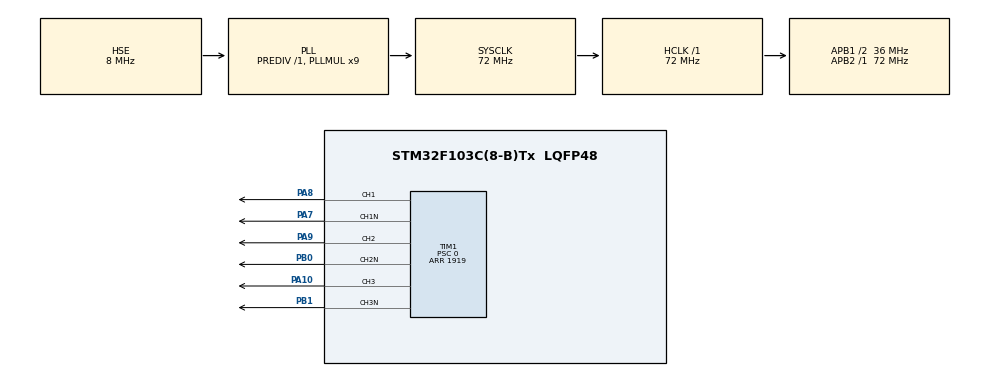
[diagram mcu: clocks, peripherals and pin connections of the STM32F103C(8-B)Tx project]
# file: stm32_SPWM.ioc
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Dma.Request0=TIM1_CH1
Dma.TIM1_CH1.0.Direction=DMA_MEMORY_TO_PERIPH
Dma.TIM1_CH1.0.Instance=DMA1_Channel2
Dma.TIM1_CH1.0.MemDataAlignment=DMA_MDATAALIGN_HALFWORD
Dma.TIM1_CH1.0.MemInc=DMA_MINC_ENABLE
Dma.TIM1_CH1.0.Mode=DMA_CIRCULAR
Dma.TIM1_CH1.0.PeriphDataAlignment=DMA_PDATAALIGN_HALFWORD
Dma.TIM1_CH1.0.PeriphInc=DMA_PINC_DISABLE
Dma.TIM1_CH1.0.Priority=DMA_PRIORITY_LOW
Mcu.Family=STM32F1
Mcu.Name=STM32F103C(8-B)Tx
Mcu.Package=LQFP48
NVIC.DMA1_Channel2_IRQn=true\:0\:0\:false\:false\:true\:false\:true\:true
NVIC.PriorityGroup=NVIC_PRIORITYGROUP_4
PA10.Signal=S_TIM1_CH3
PA7.Mode=PWM Generation1 CH1 CH1N
PA7.Signal=TIM1_CH1N
PA8.Signal=S_TIM1_CH1
PA9.Signal=S_TIM1_CH2
PB0.Mode=PWM Generation2 CH2 CH2N
PB0.Signal=TIM1_CH2N
PB1.Mode=PWM Generation3 CH3 CH3N
PB1.Signal=TIM1_CH3N
PD0-OSC_IN.Mode=HSE-External-Oscillator
PD0-OSC_IN.Signal=RCC_OSC_IN
PD1-OSC_OUT.Mode=HSE-External-Oscillator
PD1-OSC_OUT.Signal=RCC_OSC_OUT
ProjectManager.HeapSize=0x200
ProjectManager.StackSize=0x400
ProjectManager.TargetToolchain=STM32CubeIDE
RCC.AHBFreq_Value=72000000
RCC.APB1CLKDivider=RCC_HCLK_DIV2
RCC.APB1Freq_Value=36000000
RCC.APB1TimFreq_Value=72000000
RCC.APB2Freq_Value=72000000
RCC.APB2TimFreq_Value=72000000
RCC.HCLKFreq_Value=72000000
RCC.PLLMUL=RCC_PLL_MUL9
RCC.PLLSourceVirtual=RCC_PLLSOURCE_HSE
RCC.SYSCLKFreq_VALUE=72000000
RCC.SYSCLKSource=RCC_SYSCLKSOURCE_PLLCLK
RCC.USBFreq_Value=72000000
SH.S_TIM1_CH1.0=TIM1_CH1,PWM Generation1 CH1 CH1N
SH.S_TIM1_CH2.0=TIM1_CH2,PWM Generation2 CH2 CH2N
SH.S_TIM1_CH3.0=TIM1_CH3,PWM Generation3 CH3 CH3N
TIM1.AutoReloadPreload=TIM_AUTORELOAD_PRELOAD_ENABLE
TIM1.Channel-PWM\ Generation1\ CH1\ CH1N=TIM_CHANNEL_1
TIM1.Channel-PWM\ Generation2\ CH2\ CH2N=TIM_CHANNEL_2
TIM1.Channel-PWM\ Generation3\ CH3\ CH3N=TIM_CHANNEL_3
TIM1.CounterMode=TIM_COUNTERMODE_CENTERALIGNED1
TIM1.DeadTime=172
TIM1.Period=1919
TIM1.Prescaler=0
board=custom

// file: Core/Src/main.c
/* USER CODE BEGIN Header */
/**
  ******************************************************************************
  * @file           : main.c
  * @brief          : Main program body
  ******************************************************************************
  * @attention
  *
  * Copyright (c) 2024 STMicroelectronics.
  * All rights reserved.
  *
  * This software is licensed under terms that can be found in the LICENSE file
  * in the root directory of this software component.
  * If no LICENSE file comes with this software, it is provided AS-IS.
  *
  ******************************************************************************
  */
/* USER CODE END Header */
#include "main.h"

TIM_HandleTypeDef htim1;
DMA_HandleTypeDef hdma_tim1_ch1;

void SystemClock_Config(void);
static void MX_GPIO_Init(void);
static void MX_DMA_Init(void);
static void MX_TIM1_Init(void);

/* USER CODE BEGIN 0 */
uint16_t pwmData[10];
/* USER CODE END 0 */

int main(void)
{

  /* MCU Configuration--------------------------------------------------------*/

  /* Reset of all peripherals, Initializes the Flash interface and the Systick. */
  HAL_Init();

  /* Configure the system clock */
  SystemClock_Config();

  /* Initialize all configured peripherals */
  MX_GPIO_Init();
  MX_DMA_Init();
  MX_TIM1_Init();
  /* USER CODE BEGIN 2 */

  //TIM1->CCR1 = 959;
  //HAL_TIM_PWM_Start(&htim1, TIM_CHANNEL_1);
  //HAL_TIMEx_PWMN_Start(&htim1, TIM_CHANNEL_1);

  pwmData[0] = 100;
  pwmData[1] = 200;
  pwmData[2] = 300;
  pwmData[3] = 400;
  pwmData[4] = 500;
  pwmData[5] = 600;
  pwmData[6] = 700;
  pwmData[7] = 800;
  pwmData[8] = 900;
  pwmData[9] = 1000;

  HAL_TIM_PWM_Start_DMA(&htim1, TIM_CHANNEL_1, (uint32_t *)pwmData, 10);

  /* USER CODE END 2 */

  /* Infinite loop */
  while (1)
  {

  }
}

void SystemClock_Config(void)
{
  RCC_OscInitTypeDef RCC_OscInitStruct = {0};
  RCC_ClkInitTypeDef RCC_ClkInitStruct = {0};

  /** Initializes the RCC Oscillators according to the specified parameters
  * in the RCC_OscInitTypeDef structure.
  */
  RCC_OscInitStruct.OscillatorType = RCC_OSCILLATORTYPE_HSE;
  RCC_OscInitStruct.HSEState = RCC_HSE_ON;
  RCC_OscInitStruct.HSEPredivValue = RCC_HSE_PREDIV_DIV1;
  RCC_OscInitStruct.HSIState = RCC_HSI_ON;
  RCC_OscInitStruct.PLL.PLLState = RCC_PLL_ON;
  RCC_OscInitStruct.PLL.PLLSource = RCC_PLLSOURCE_HSE;
  RCC_OscInitStruct.PLL.PLLMUL = RCC_PLL_MUL9;
  if (HAL_RCC_OscConfig(&RCC_OscInitStruct) != HAL_OK)
  {
    Error_Handler();
  }

  /** Initializes the CPU, AHB and APB buses clocks
  */
  RCC_ClkInitStruct.ClockType = RCC_CLOCKTYPE_HCLK|RCC_CLOCKTYPE_SYSCLK
                              |RCC_CLOCKTYPE_PCLK1|RCC_CLOCKTYPE_PCLK2;
  RCC_ClkInitStruct.SYSCLKSource = RCC_SYSCLKSOURCE_PLLCLK;
  RCC_ClkInitStruct.AHBCLKDivider = RCC_SYSCLK_DIV1;
  RCC_ClkInitStruct.APB1CLKDivider = RCC_HCLK_DIV2;
  RCC_ClkInitStruct.APB2CLKDivider = RCC_HCLK_DIV1;

  if (HAL_RCC_ClockConfig(&RCC_ClkInitStruct, FLASH_LATENCY_2) != HAL_OK)
  {
    Error_Handler();
  }
}

static void MX_TIM1_Init(void)
{

  TIM_MasterConfigTypeDef sMasterConfig = {0};
  TIM_OC_InitTypeDef sConfigOC = {0};
  TIM_BreakDeadTimeConfigTypeDef sBreakDeadTimeConfig = {0};

  htim1.Instance = TIM1;
  htim1.Init.Prescaler = 0;
  htim1.Init.CounterMode = TIM_COUNTERMODE_CENTERALIGNED1;
  htim1.Init.Period = 1919;
  htim1.Init.ClockDivision = TIM_CLOCKDIVISION_DIV1;
  htim1.Init.RepetitionCounter = 0;
  htim1.Init.AutoReloadPreload = TIM_AUTORELOAD_PRELOAD_ENABLE;
  if (HAL_TIM_PWM_Init(&htim1) != HAL_OK)
  {
    Error_Handler();
  }
  sMasterConfig.MasterOutputTrigger = TIM_TRGO_RESET;
  sMasterConfig.MasterSlaveMode = TIM_MASTERSLAVEMODE_DISABLE;
  if (HAL_TIMEx_MasterConfigSynchronization(&htim1, &sMasterConfig) != HAL_OK)
  {
    Error_Handler();
  }
  sConfigOC.OCMode = TIM_OCMODE_PWM1;
  sConfigOC.Pulse = 0;
  sConfigOC.OCPolarity = TIM_OCPOLARITY_HIGH;
  sConfigOC.OCNPolarity = TIM_OCNPOLARITY_HIGH;
  sConfigOC.OCFastMode = TIM_OCFAST_DISABLE;
  sConfigOC.OCIdleState = TIM_OCIDLESTATE_RESET;
  sConfigOC.OCNIdleState = TIM_OCNIDLESTATE_RESET;
  if (HAL_TIM_PWM_ConfigChannel(&htim1, &sConfigOC, TIM_CHANNEL_1) != HAL_OK)
  {
    Error_Handler();
  }
  if (HAL_TIM_PWM_ConfigChannel(&htim1, &sConfigOC, TIM_CHANNEL_2) != HAL_OK)
  {
    Error_Handler();
  }
  if (HAL_TIM_PWM_ConfigChannel(&htim1, &sConfigOC, TIM_CHANNEL_3) != HAL_OK)
  {
    Error_Handler();
  }
  sBreakDeadTimeConfig.OffStateRunMode = TIM_OSSR_DISABLE;
  sBreakDeadTimeConfig.OffStateIDLEMode = TIM_OSSI_DISABLE;
  sBreakDeadTimeConfig.LockLevel = TIM_LOCKLEVEL_OFF;
  sBreakDeadTimeConfig.DeadTime = 172;
  sBreakDeadTimeConfig.BreakState = TIM_BREAK_DISABLE;
  sBreakDeadTimeConfig.BreakPolarity = TIM_BREAKPOLARITY_HIGH;
  sBreakDeadTimeConfig.AutomaticOutput = TIM_AUTOMATICOUTPUT_DISABLE;
  if (HAL_TIMEx_ConfigBreakDeadTime(&htim1, &sBreakDeadTimeConfig) != HAL_OK)
  {
    Error_Handler();
  }
  HAL_TIM_MspPostInit(&htim1);

}

static void MX_DMA_Init(void)
{

  /* DMA controller clock enable */
  __HAL_RCC_DMA1_CLK_ENABLE();

  /* DMA interrupt init */
  /* DMA1_Channel2_IRQn interrupt configuration */
  HAL_NVIC_SetPriority(DMA1_Channel2_IRQn, 0, 0);
  HAL_NVIC_EnableIRQ(DMA1_Channel2_IRQn);

}

static void MX_GPIO_Init(void)
{

  /* GPIO Ports Clock Enable */
  __HAL_RCC_GPIOD_CLK_ENABLE();
  __HAL_RCC_GPIOA_CLK_ENABLE();
  __HAL_RCC_GPIOB_CLK_ENABLE();

}

void Error_Handler(void)
{
  __disable_irq();
  while (1)
  {
  }
}
